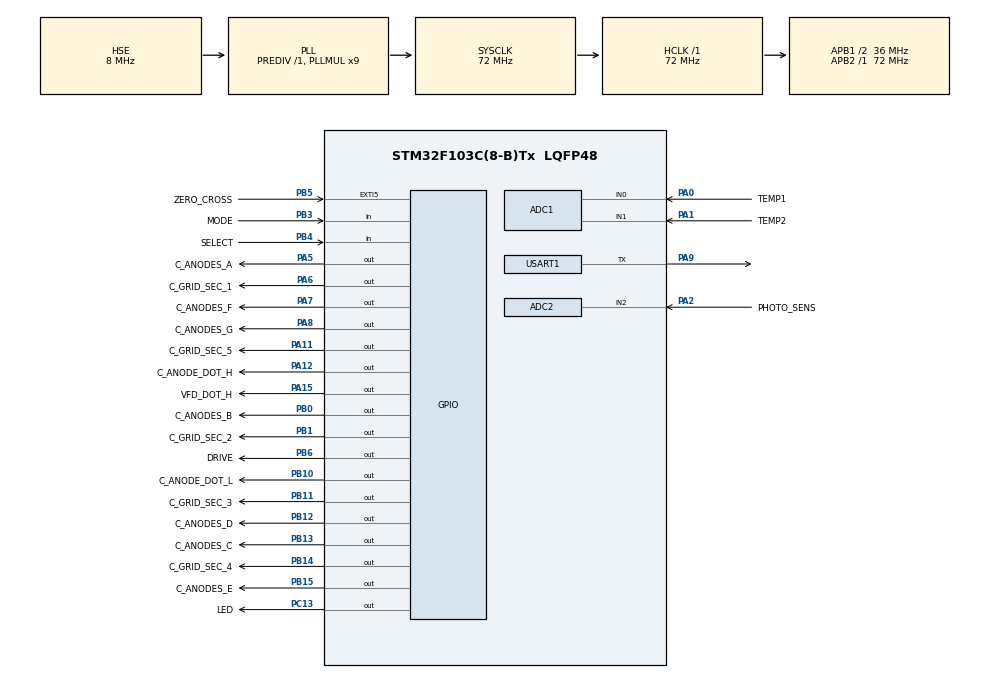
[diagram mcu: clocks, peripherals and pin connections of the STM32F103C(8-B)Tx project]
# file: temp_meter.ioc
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ADC1.Channel-4\#ChannelRegularConversion=ADC_CHANNEL_0
ADC1.Channel-5\#ChannelRegularConversion=ADC_CHANNEL_1
ADC1.ContinuousConvMode=ENABLE
ADC1.DataAlign=ADC_DATAALIGN_RIGHT
ADC1.DiscontinuousConvMode=DISABLE
ADC1.EnableAnalogWatchDog=false
ADC1.EnableRegularConversion=ENABLE
ADC1.ExternalTrigConv=ADC_SOFTWARE_START
ADC1.InjNumberOfConversion=0
ADC1.NbrOfConversion=2
ADC1.NbrOfConversionFlag=1
ADC1.Rank-4\#ChannelRegularConversion=1
ADC1.Rank-5\#ChannelRegularConversion=2
ADC1.SamplingTime-4\#ChannelRegularConversion=ADC_SAMPLETIME_55CYCLES_5
ADC1.SamplingTime-5\#ChannelRegularConversion=ADC_SAMPLETIME_55CYCLES_5
ADC1.ScanConvMode=ADC_SCAN_ENABLE
ADC1.master=1
ADC2.Channel-0\#ChannelRegularConversion=ADC_CHANNEL_2
ADC2.ContinuousConvMode=ENABLE
ADC2.DataAlign=ADC_DATAALIGN_RIGHT
ADC2.DiscontinuousConvMode=DISABLE
ADC2.EnableAnalogWatchDog=false
ADC2.EnableRegularConversion=ENABLE
ADC2.ExternalTrigConv=ADC_SOFTWARE_START
ADC2.InjNumberOfConversion=0
ADC2.NbrOfConversion=1
ADC2.NbrOfConversionFlag=1
ADC2.Rank-0\#ChannelRegularConversion=1
ADC2.SamplingTime-0\#ChannelRegularConversion=ADC_SAMPLETIME_1CYCLE_5
ADC2.ScanConvMode=ADC_SCAN_DISABLE
Dma.ADC1.0.Direction=DMA_PERIPH_TO_MEMORY
Dma.ADC1.0.Instance=DMA1_Channel1
Dma.ADC1.0.MemDataAlignment=DMA_MDATAALIGN_HALFWORD
Dma.ADC1.0.MemInc=DMA_MINC_ENABLE
Dma.ADC1.0.Mode=DMA_NORMAL
Dma.ADC1.0.PeriphDataAlignment=DMA_PDATAALIGN_HALFWORD
Dma.ADC1.0.PeriphInc=DMA_PINC_DISABLE
Dma.ADC1.0.Priority=DMA_PRIORITY_LOW
Dma.Request0=ADC1
Mcu.Family=STM32F1
Mcu.Name=STM32F103C(8-B)Tx
Mcu.Package=LQFP48
NVIC.DMA1_Channel1_IRQn=true\:0\:0\:false\:false\:true\:false
NVIC.EXTI9_5_IRQn=true\:0\:0\:false\:false\:true\:true
NVIC.PriorityGroup=NVIC_PRIORITYGROUP_4
NVIC.TIM3_IRQn=true\:0\:0\:false\:false\:true\:true
NVIC.TIM4_IRQn=true\:0\:0\:false\:false\:true\:true
PA0-WKUP.GPIO_Label=TEMP1
PA0-WKUP.Signal=ADCx_IN0
PA1.GPIO_Label=TEMP2
PA1.Signal=ADCx_IN1
PA11.GPIO_Label=C_GRID_SEC_5
PA11.Signal=GPIO_Output
PA12.GPIO_Label=C_ANODE_DOT_H
PA12.Signal=GPIO_Output
PA15.GPIO_Label=VFD_DOT_H
PA15.Signal=GPIO_Output
PA2.GPIO_Label=PHOTO_SENS
PA2.Signal=ADCx_IN2
PA5.GPIO_Label=C_ANODES_A
PA5.Signal=GPIO_Output
PA6.GPIO_Label=C_GRID_SEC_1
PA6.Signal=GPIO_Output
PA7.GPIO_Label=C_ANODES_F
PA7.Signal=GPIO_Output
PA8.GPIO_Label=C_ANODES_G
PA8.Signal=GPIO_Output
PA9.Mode=Half_duplex(single_wire_mode)
PA9.Signal=USART1_TX
PB0.GPIO_Label=C_ANODES_B
PB0.Signal=GPIO_Output
PB1.GPIO_Label=C_GRID_SEC_2
PB1.Signal=GPIO_Output
PB10.GPIO_Label=C_ANODE_DOT_L
PB10.Signal=GPIO_Output
PB11.GPIO_Label=C_GRID_SEC_3
PB11.Signal=GPIO_Output
PB12.GPIO_Label=C_ANODES_D
PB12.Signal=GPIO_Output
PB13.GPIO_Label=C_ANODES_C
PB13.Signal=GPIO_Output
PB14.GPIO_Label=C_GRID_SEC_4
PB14.Signal=GPIO_Output
PB15.GPIO_Label=C_ANODES_E
PB15.Signal=GPIO_Output
PB3.GPIO_Label=MODE
PB3.GPIO_PuPd=GPIO_PULLUP
PB3.Signal=GPIO_Input
PB4.GPIO_Label=SELECT
PB4.GPIO_PuPd=GPIO_PULLUP
PB4.Signal=GPIO_Input
PB5.GPIO_Label=ZERO_CROSS
PB5.GPIO_ModeDefaultEXTI=GPIO_MODE_IT_FALLING
PB5.Signal=GPXTI5
PB6.GPIO_Label=DRIVE
PB6.GPIO_Speed=GPIO_SPEED_FREQ_MEDIUM
PB6.Signal=GPIO_Output
PC13-TAMPER-RTC.GPIO_Label=LED
PC13-TAMPER-RTC.Signal=GPIO_Output
PD0-OSC_IN.Mode=HSE-External-Oscillator
PD0-OSC_IN.Signal=RCC_OSC_IN
PD1-OSC_OUT.Mode=HSE-External-Oscillator
PD1-OSC_OUT.Signal=RCC_OSC_OUT
ProjectManager.HeapSize=0x200
ProjectManager.StackSize=0x400
ProjectManager.TargetToolchain=Makefile
RCC.ADCPresc=RCC_ADCPCLK2_DIV8
RCC.AHBFreq_Value=72000000
RCC.APB1CLKDivider=RCC_HCLK_DIV2
RCC.APB1Freq_Value=36000000
RCC.APB1TimFreq_Value=72000000
RCC.APB2Freq_Value=72000000
RCC.APB2TimFreq_Value=72000000
RCC.EnbaleCSS=true
RCC.HCLKFreq_Value=72000000
RCC.PLLMUL=RCC_PLL_MUL9
RCC.PLLSourceVirtual=RCC_PLLSOURCE_HSE
RCC.SYSCLKFreq_VALUE=72000000
RCC.SYSCLKSource=RCC_SYSCLKSOURCE_PLLCLK
RCC.USBFreq_Value=72000000
SH.ADCx_IN0.0=ADC1_IN0,IN0
SH.ADCx_IN1.0=ADC1_IN1,IN1
SH.ADCx_IN2.0=ADC2_IN2,IN2
TIM3.ClockDivision=TIM_CLOCKDIVISION_DIV1
TIM3.Period=10
TIM3.Prescaler=7200
TIM4.ClockDivision=TIM_CLOCKDIVISION_DIV4
TIM4.Period=5
TIM4.Prescaler=1000
TIM4.TIM_MasterOutputTrigger=TIM_TRGO_OC1
USART1.BaudRate=9600
USART1.Mode=MODE_TX
USART1.VirtualMode=VM_ASYNC
VP_SYS_VS_ND.Mode=No_Debug
VP_TIM3_VS_ClockSourceINT.Mode=Internal
VP_TIM4_VS_ClockSourceINT.Mode=Internal
board=temp_meter

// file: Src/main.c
/**
  ******************************************************************************
  * @file           : main.c
  * @brief          : Main program body
  ******************************************************************************
  ** This notice applies to any and all portions of this file
  * that are not between comment pairs USER CODE BEGIN and
  * USER CODE END. Other portions of this file, whether
  * inserted by the user or by software development tools
  * are owned by their respective copyright owners.
  *
  * COPYRIGHT(c) 2019 STMicroelectronics
  *
  * Redistribution and use in source and binary forms, with or without modification,
  * are permitted provided that the following conditions are met:
  *   1. Redistributions of source code must retain the above copyright notice,
  *      this list of conditions and the following disclaimer.
  *   2. Redistributions in binary form must reproduce the above copyright notice,
  *      this list of conditions and the following disclaimer in the documentation
  *      and/or other materials provided with the distribution.
  *   3. Neither the name of STMicroelectronics nor the names of its contributors
  *      may be used to endorse or promote products derived from this software
  *      without specific prior written permission.
  *
  * THIS SOFTWARE IS PROVIDED BY THE COPYRIGHT HOLDERS AND CONTRIBUTORS "AS IS"
  * AND ANY EXPRESS OR IMPLIED WARRANTIES, INCLUDING, BUT NOT LIMITED TO, THE
  * IMPLIED WARRANTIES OF MERCHANTABILITY AND FITNESS FOR A PARTICULAR PURPOSE ARE
  * DISCLAIMED. IN NO EVENT SHALL THE COPYRIGHT HOLDER OR CONTRIBUTORS BE LIABLE
  * FOR ANY DIRECT, INDIRECT, INCIDENTAL, SPECIAL, EXEMPLARY, OR CONSEQUENTIAL
  * DAMAGES (INCLUDING, BUT NOT LIMITED TO, PROCUREMENT OF SUBSTITUTE GOODS OR
  * SERVICES; LOSS OF USE, DATA, OR PROFITS; OR BUSINESS INTERRUPTION) HOWEVER
  * CAUSED AND ON ANY THEORY OF LIABILITY, WHETHER IN CONTRACT, STRICT LIABILITY,
  * OR TORT (INCLUDING NEGLIGENCE OR OTHERWISE) ARISING IN ANY WAY OUT OF THE USE
  * OF THIS SOFTWARE, EVEN IF ADVISED OF THE POSSIBILITY OF SUCH DAMAGE.
  *
  ******************************************************************************
  */
#include "main.h"
#include "stm32f1xx_hal.h"

/* USER CODE BEGIN Includes */

#include "vfd_driver.h"
#include "fan_driver.h"
#include "logic.h"
#include "usart.h"

/* USER CODE END Includes */

ADC_HandleTypeDef hadc1;
ADC_HandleTypeDef hadc2;
DMA_HandleTypeDef hdma_adc1;

TIM_HandleTypeDef htim3;
TIM_HandleTypeDef htim4;

UART_HandleTypeDef huart1;

/* USER CODE BEGIN PV */
/* Private variables ---------------------------------------------------------*/

/* USER CODE END PV */

void SystemClock_Config(void);
static void MX_GPIO_Init(void);
static void MX_DMA_Init(void);
static void MX_ADC1_Init(void);
static void MX_TIM3_Init(void);
static void MX_ADC2_Init(void);
static void MX_USART1_UART_Init(void);
static void MX_TIM4_Init(void);

/* USER CODE BEGIN PFP */
/* Private function prototypes -----------------------------------------------*/

/* USER CODE END PFP */

int main(void)
{

  /* MCU Configuration----------------------------------------------------------*/

  /* Reset of all peripherals, Initializes the Flash interface and the Systick. */
  HAL_Init();

  /* Configure the system clock */
  SystemClock_Config();

  /* Initialize all configured peripherals */
  MX_GPIO_Init();
  MX_DMA_Init();
  MX_ADC1_Init();
  MX_TIM3_Init();
  MX_ADC2_Init();
  MX_USART1_UART_Init();
  MX_TIM4_Init();
  /* USER CODE BEGIN 2 */

  vfd_driver_init();
  fan_driver_init(&htim3);
  usart_config(&huart1);
  logic_init(&hadc1, &hadc2);

  // HAL_TIM_Base_Start_IT(&htim3);
  HAL_TIM_Base_Start_IT(&htim4);

  LOG("Initialized");

  logic_init_selfcheck();

  /* USER CODE END 2 */

  /* Infinite loop */
  /* USER CODE BEGIN WHILE */
  while (1)
  {
    logic_update();
  /* USER CODE END WHILE */

  }

}

void SystemClock_Config(void)
{

  RCC_OscInitTypeDef RCC_OscInitStruct;
  RCC_ClkInitTypeDef RCC_ClkInitStruct;
  RCC_PeriphCLKInitTypeDef PeriphClkInit;

    /**Initializes the CPU, AHB and APB busses clocks
    */
  RCC_OscInitStruct.OscillatorType = RCC_OSCILLATORTYPE_HSE;
  RCC_OscInitStruct.HSEState = RCC_HSE_ON;
  RCC_OscInitStruct.HSEPredivValue = RCC_HSE_PREDIV_DIV1;
  RCC_OscInitStruct.HSIState = RCC_HSI_ON;
  RCC_OscInitStruct.PLL.PLLState = RCC_PLL_ON;
  RCC_OscInitStruct.PLL.PLLSource = RCC_PLLSOURCE_HSE;
  RCC_OscInitStruct.PLL.PLLMUL = RCC_PLL_MUL9;
  if (HAL_RCC_OscConfig(&RCC_OscInitStruct) != HAL_OK)
  {
    _Error_Handler(__FILE__, __LINE__);
  }

    /**Initializes the CPU, AHB and APB busses clocks
    */
  RCC_ClkInitStruct.ClockType = RCC_CLOCKTYPE_HCLK|RCC_CLOCKTYPE_SYSCLK
                              |RCC_CLOCKTYPE_PCLK1|RCC_CLOCKTYPE_PCLK2;
  RCC_ClkInitStruct.SYSCLKSource = RCC_SYSCLKSOURCE_PLLCLK;
  RCC_ClkInitStruct.AHBCLKDivider = RCC_SYSCLK_DIV1;
  RCC_ClkInitStruct.APB1CLKDivider = RCC_HCLK_DIV2;
  RCC_ClkInitStruct.APB2CLKDivider = RCC_HCLK_DIV1;

  if (HAL_RCC_ClockConfig(&RCC_ClkInitStruct, FLASH_LATENCY_2) != HAL_OK)
  {
    _Error_Handler(__FILE__, __LINE__);
  }

  PeriphClkInit.PeriphClockSelection = RCC_PERIPHCLK_ADC;
  PeriphClkInit.AdcClockSelection = RCC_ADCPCLK2_DIV8;
  if (HAL_RCCEx_PeriphCLKConfig(&PeriphClkInit) != HAL_OK)
  {
    _Error_Handler(__FILE__, __LINE__);
  }

    /**Enables the Clock Security System
    */
  HAL_RCC_EnableCSS();

    /**Configure the Systick interrupt time
    */
  HAL_SYSTICK_Config(HAL_RCC_GetHCLKFreq()/1000);

    /**Configure the Systick
    */
  HAL_SYSTICK_CLKSourceConfig(SYSTICK_CLKSOURCE_HCLK);

  /* SysTick_IRQn interrupt configuration */
  HAL_NVIC_SetPriority(SysTick_IRQn, 0, 0);
}

/* ADC1 init function */
static void MX_ADC1_Init(void)
{

  ADC_ChannelConfTypeDef sConfig;

    /**Common config
    */
  hadc1.Instance = ADC1;
  hadc1.Init.ScanConvMode = ADC_SCAN_ENABLE;
  hadc1.Init.ContinuousConvMode = ENABLE;
  hadc1.Init.DiscontinuousConvMode = DISABLE;
  hadc1.Init.ExternalTrigConv = ADC_SOFTWARE_START;
  hadc1.Init.DataAlign = ADC_DATAALIGN_RIGHT;
  hadc1.Init.NbrOfConversion = 2;
  if (HAL_ADC_Init(&hadc1) != HAL_OK)
  {
    _Error_Handler(__FILE__, __LINE__);
  }

    /**Configure Regular Channel
    */
  sConfig.Channel = ADC_CHANNEL_0;
  sConfig.Rank = ADC_REGULAR_RANK_1;
  sConfig.SamplingTime = ADC_SAMPLETIME_55CYCLES_5;
  if (HAL_ADC_ConfigChannel(&hadc1, &sConfig) != HAL_OK)
  {
    _Error_Handler(__FILE__, __LINE__);
  }

    /**Configure Regular Channel
    */
  sConfig.Channel = ADC_CHANNEL_1;
  sConfig.Rank = ADC_REGULAR_RANK_2;
  if (HAL_ADC_ConfigChannel(&hadc1, &sConfig) != HAL_OK)
  {
    _Error_Handler(__FILE__, __LINE__);
  }

}

/* ADC2 init function */
static void MX_ADC2_Init(void)
{

  ADC_ChannelConfTypeDef sConfig;

    /**Common config
    */
  hadc2.Instance = ADC2;
  hadc2.Init.ScanConvMode = ADC_SCAN_DISABLE;
  hadc2.Init.ContinuousConvMode = ENABLE;
  hadc2.Init.DiscontinuousConvMode = DISABLE;
  hadc2.Init.ExternalTrigConv = ADC_SOFTWARE_START;
  hadc2.Init.DataAlign = ADC_DATAALIGN_RIGHT;
  hadc2.Init.NbrOfConversion = 1;
  if (HAL_ADC_Init(&hadc2) != HAL_OK)
  {
    _Error_Handler(__FILE__, __LINE__);
  }

    /**Configure Regular Channel
    */
  sConfig.Channel = ADC_CHANNEL_2;
  sConfig.Rank = ADC_REGULAR_RANK_1;
  sConfig.SamplingTime = ADC_SAMPLETIME_1CYCLE_5;
  if (HAL_ADC_ConfigChannel(&hadc2, &sConfig) != HAL_OK)
  {
    _Error_Handler(__FILE__, __LINE__);
  }

}

/* TIM3 init function */
static void MX_TIM3_Init(void)
{

  TIM_ClockConfigTypeDef sClockSourceConfig;
  TIM_MasterConfigTypeDef sMasterConfig;

  htim3.Instance = TIM3;
  htim3.Init.Prescaler = 7200;
  htim3.Init.CounterMode = TIM_COUNTERMODE_UP;
  htim3.Init.Period = 10;
  htim3.Init.ClockDivision = TIM_CLOCKDIVISION_DIV1;
  htim3.Init.AutoReloadPreload = TIM_AUTORELOAD_PRELOAD_DISABLE;
  if (HAL_TIM_Base_Init(&htim3) != HAL_OK)
  {
    _Error_Handler(__FILE__, __LINE__);
  }

  sClockSourceConfig.ClockSource = TIM_CLOCKSOURCE_INTERNAL;
  if (HAL_TIM_ConfigClockSource(&htim3, &sClockSourceConfig) != HAL_OK)
  {
    _Error_Handler(__FILE__, __LINE__);
  }

  sMasterConfig.MasterOutputTrigger = TIM_TRGO_RESET;
  sMasterConfig.MasterSlaveMode = TIM_MASTERSLAVEMODE_DISABLE;
  if (HAL_TIMEx_MasterConfigSynchronization(&htim3, &sMasterConfig) != HAL_OK)
  {
    _Error_Handler(__FILE__, __LINE__);
  }

}

/* TIM4 init function */
static void MX_TIM4_Init(void)
{

  TIM_ClockConfigTypeDef sClockSourceConfig;
  TIM_MasterConfigTypeDef sMasterConfig;

  htim4.Instance = TIM4;
  htim4.Init.Prescaler = 1000;
  htim4.Init.CounterMode = TIM_COUNTERMODE_UP;
  htim4.Init.Period = 5;
  htim4.Init.ClockDivision = TIM_CLOCKDIVISION_DIV4;
  htim4.Init.AutoReloadPreload = TIM_AUTORELOAD_PRELOAD_DISABLE;
  if (HAL_TIM_Base_Init(&htim4) != HAL_OK)
  {
    _Error_Handler(__FILE__, __LINE__);
  }

  sClockSourceConfig.ClockSource = TIM_CLOCKSOURCE_INTERNAL;
  if (HAL_TIM_ConfigClockSource(&htim4, &sClockSourceConfig) != HAL_OK)
  {
    _Error_Handler(__FILE__, __LINE__);
  }

  sMasterConfig.MasterOutputTrigger = TIM_TRGO_OC1;
  sMasterConfig.MasterSlaveMode = TIM_MASTERSLAVEMODE_DISABLE;
  if (HAL_TIMEx_MasterConfigSynchronization(&htim4, &sMasterConfig) != HAL_OK)
  {
    _Error_Handler(__FILE__, __LINE__);
  }

}

/* USART1 init function */
static void MX_USART1_UART_Init(void)
{

  huart1.Instance = USART1;
  huart1.Init.BaudRate = 9600;
  huart1.Init.WordLength = UART_WORDLENGTH_8B;
  huart1.Init.StopBits = UART_STOPBITS_1;
  huart1.Init.Parity = UART_PARITY_NONE;
  huart1.Init.Mode = UART_MODE_TX;
  huart1.Init.HwFlowCtl = UART_HWCONTROL_NONE;
  huart1.Init.OverSampling = UART_OVERSAMPLING_16;
  if (HAL_HalfDuplex_Init(&huart1) != HAL_OK)
  {
    _Error_Handler(__FILE__, __LINE__);
  }

}

static void MX_DMA_Init(void)
{
  /* DMA controller clock enable */
  __HAL_RCC_DMA1_CLK_ENABLE();

  /* DMA interrupt init */
  /* DMA1_Channel1_IRQn interrupt configuration */
  HAL_NVIC_SetPriority(DMA1_Channel1_IRQn, 0, 0);
  HAL_NVIC_EnableIRQ(DMA1_Channel1_IRQn);

}

/** Configure pins as
        * Analog
        * Input
        * Output
        * EVENT_OUT
        * EXTI
*/
static void MX_GPIO_Init(void)
{

  GPIO_InitTypeDef GPIO_InitStruct;

  /* GPIO Ports Clock Enable */
  __HAL_RCC_GPIOC_CLK_ENABLE();
  __HAL_RCC_GPIOD_CLK_ENABLE();
  __HAL_RCC_GPIOA_CLK_ENABLE();
  __HAL_RCC_GPIOB_CLK_ENABLE();

  /*Configure GPIO pin Output Level */
  HAL_GPIO_WritePin(LED_GPIO_Port, LED_Pin, GPIO_PIN_RESET);

  /*Configure GPIO pin Output Level */
  HAL_GPIO_WritePin(GPIOA, C_ANODES_A_Pin|C_GRID_SEC_1_Pin|C_ANODES_F_Pin|C_ANODES_G_Pin
                          |C_GRID_SEC_5_Pin|C_ANODE_DOT_H_Pin|VFD_DOT_H_Pin, GPIO_PIN_RESET);

  /*Configure GPIO pin Output Level */
  HAL_GPIO_WritePin(GPIOB, C_ANODES_B_Pin|C_GRID_SEC_2_Pin|C_ANODE_DOT_L_Pin|C_GRID_SEC_3_Pin
                          |C_ANODES_D_Pin|C_ANODES_C_Pin|C_GRID_SEC_4_Pin|C_ANODES_E_Pin
                          |DRIVE_Pin, GPIO_PIN_RESET);

  /*Configure GPIO pin : LED_Pin */
  GPIO_InitStruct.Pin = LED_Pin;
  GPIO_InitStruct.Mode = GPIO_MODE_OUTPUT_PP;
  GPIO_InitStruct.Speed = GPIO_SPEED_FREQ_LOW;
  HAL_GPIO_Init(LED_GPIO_Port, &GPIO_InitStruct);

  /*Configure GPIO pins : C_ANODES_A_Pin C_GRID_SEC_1_Pin C_ANODES_F_Pin C_ANODES_G_Pin
                           C_GRID_SEC_5_Pin C_ANODE_DOT_H_Pin VFD_DOT_H_Pin */
  GPIO_InitStruct.Pin = C_ANODES_A_Pin|C_GRID_SEC_1_Pin|C_ANODES_F_Pin|C_ANODES_G_Pin
                          |C_GRID_SEC_5_Pin|C_ANODE_DOT_H_Pin|VFD_DOT_H_Pin;
  GPIO_InitStruct.Mode = GPIO_MODE_OUTPUT_PP;
  GPIO_InitStruct.Speed = GPIO_SPEED_FREQ_LOW;
  HAL_GPIO_Init(GPIOA, &GPIO_InitStruct);

  /*Configure GPIO pins : C_ANODES_B_Pin C_GRID_SEC_2_Pin C_ANODE_DOT_L_Pin C_GRID_SEC_3_Pin
                           C_ANODES_D_Pin C_ANODES_C_Pin C_GRID_SEC_4_Pin C_ANODES_E_Pin */
  GPIO_InitStruct.Pin = C_ANODES_B_Pin|C_GRID_SEC_2_Pin|C_ANODE_DOT_L_Pin|C_GRID_SEC_3_Pin
                          |C_ANODES_D_Pin|C_ANODES_C_Pin|C_GRID_SEC_4_Pin|C_ANODES_E_Pin;
  GPIO_InitStruct.Mode = GPIO_MODE_OUTPUT_PP;
  GPIO_InitStruct.Speed = GPIO_SPEED_FREQ_LOW;
  HAL_GPIO_Init(GPIOB, &GPIO_InitStruct);

  /*Configure GPIO pins : MODE_Pin SELECT_Pin */
  GPIO_InitStruct.Pin = MODE_Pin|SELECT_Pin;
  GPIO_InitStruct.Mode = GPIO_MODE_INPUT;
  GPIO_InitStruct.Pull = GPIO_PULLUP;
  HAL_GPIO_Init(GPIOB, &GPIO_InitStruct);

  /*Configure GPIO pin : ZERO_CROSS_Pin */
  GPIO_InitStruct.Pin = ZERO_CROSS_Pin;
  GPIO_InitStruct.Mode = GPIO_MODE_IT_FALLING;
  GPIO_InitStruct.Pull = GPIO_NOPULL;
  HAL_GPIO_Init(ZERO_CROSS_GPIO_Port, &GPIO_InitStruct);

  /*Configure GPIO pin : DRIVE_Pin */
  GPIO_InitStruct.Pin = DRIVE_Pin;
  GPIO_InitStruct.Mode = GPIO_MODE_OUTPUT_PP;
  GPIO_InitStruct.Speed = GPIO_SPEED_FREQ_MEDIUM;
  HAL_GPIO_Init(DRIVE_GPIO_Port, &GPIO_InitStruct);

  /* EXTI interrupt init*/
  HAL_NVIC_SetPriority(EXTI9_5_IRQn, 0, 0);
  HAL_NVIC_EnableIRQ(EXTI9_5_IRQn);

}

void _Error_Handler(char *file, int line)
{
  while(1)
  {
  }
}

/************************ (C) COPYRIGHT STMicroelectronics *****END OF FILE****/
